# PY32F040xx register map
Vendor: Puya; Series: PY32F0; File version: 1.0.0
CPU: CM0+ r0p1, little endian, no MPU, no FPU, 4 interrupt priority bits
Registers are 32-bit, read-write, reset 0x0 unless marked. A register's access mark holds for its fields unless they carry their own. Offsets are from the block's base; [hi:lo] are bit positions; {n}, {i} and the like mark numbered series; 'fields as' and 'values as' point back to an identical list.

## COMP1 — Comparator 1
Base 0x40010200
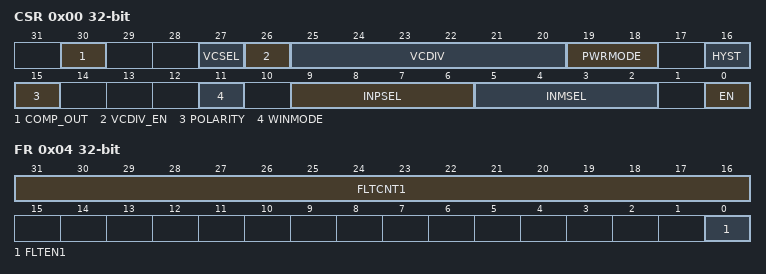
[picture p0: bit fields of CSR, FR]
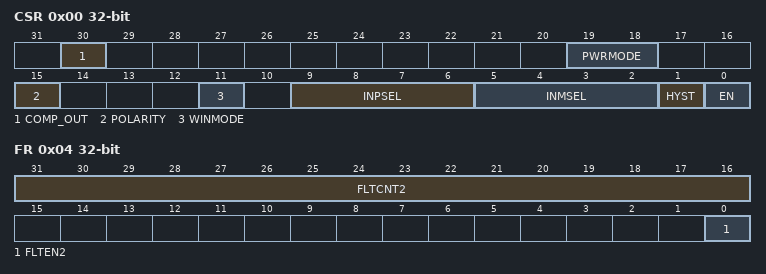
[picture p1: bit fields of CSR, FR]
0x00 CSR — COMP control and status register
  [30] COMP_OUT — Comparator output status
  [27] VCSEL
  [26] VCDIV_EN
  [25:20] VCDIV
    1=0; 2=1; 4=2; 8=3; 16=4; 32=5
  [19:18] PWRMODE — Comparator power mode selector
    1=0; 2=1
  [16] HYST — Comparator hysteresis enable selector
  [15] POLARITY — Comparator polarity selector
  [11] WINMODE — Comparator non-inverting input selector for window mode
  [9:6] INPSEL — Comparator signal selector for non-inverting input
    1=0; 2=1; 4=2; 8=3
  [5:2] INMSEL — Comparator signal selector for inverting input INM
  [0] EN — COMP enable bit
0x04 FR — Comparator Filter register
  [31:16] FLTCNT1 — Comparator filter and counter
  [0] FLTEN1 — Filter enable bit

## COMP2 — Comparator2
Base 0x40010210
0x00 CSR — COMP control and status register
  [30] COMP_OUT — Comparator output status
  [19:18] PWRMODE — Comparator power mode selector
    1=0; 2=1
  [15] POLARITY — Comparator polarity selector
  [11] WINMODE — Comparator non-inverting input selector for window mode
  [9:6] INPSEL — Comparator signal selector for non-inverting input
    1=0; 2=1; 4=2; 8=3
  [5:2] INMSEL — Comparator signal selector for inverting input INM
  [1] HYST — Comparator hysteresis enable selector
  [0] EN — COMP enable bit
0x04 FR — Comparator Filter register
  [31:16] FLTCNT2 — Comparator filter and counter
  [0] FLTEN2 — Filter enable bit

## CRC — CRC calculation unit
Base 0x40023000
0x00 DR reset 0xFFFFFFFF — Data register
  [31:0] DR — Data Register
0x04 IDR — Independent Data register
  [7:0] IDR
0x08 CR wo — Control register
  [0] RESET — Reset bit

## CTC
Base 0x40006C00
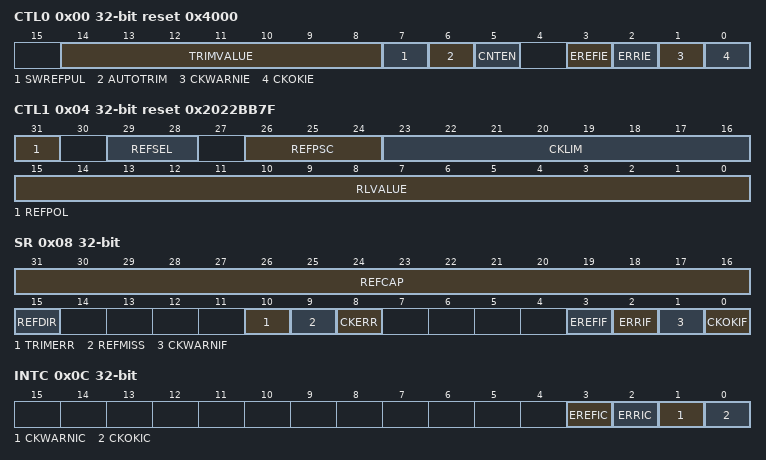
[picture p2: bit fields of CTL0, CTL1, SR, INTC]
0x00 CTL0 reset 0x4000
  [14:8] TRIMVALUE, [7] SWREFPUL wo, [6] AUTOTRIM, [5] CNTEN, [3] EREFIE, [2] ERRIE, [1] CKWARNIE, [0] CKOKIE
0x04 CTL1 reset 0x2022BB7F
  [31] REFPOL
  [29:28] REFSEL
    1=0; 2=1
  [26:24] REFPSC
    1=0; 2=1; 4=2
  [23:16] CKLIM
  [15:0] RLVALUE
0x08 SR ro
  [31:16] REFCAP, [15] REFDIR, [10] TRIMERR, [9] REFMISS, [8] CKERR, [3] EREFIF, [2] ERRIF, [1] CKWARNIF, [0] CKOKIF
0x0C INTC wo
  [3] EREFIC, [2] ERRIC, [1] CKWARNIC, [0] CKOKIC

## DBGMCU — Debug support
Base 0x40015800
0x00 IDCODE ro — MCU Device ID Code Register
  [30:0] REV_ID
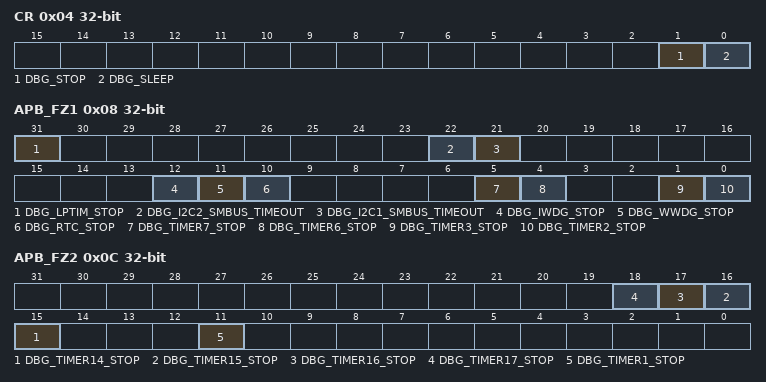
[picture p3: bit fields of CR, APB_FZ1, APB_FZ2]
0x04 CR — Debug MCU Configuration Register
  [1] DBG_STOP — Debug Stop Mode
  [0] DBG_SLEEP — Debug Sleep Mode
0x08 APB_FZ1 — APB Freeze Register1
  [31] DBG_LPTIM_STOP — Debug LPTIM stopped when Core is halted
  [22] DBG_I2C2_SMBUS_TIMEOUT ro
  [21] DBG_I2C1_SMBUS_TIMEOUT
  [12] DBG_IWDG_STOP — Debug Independent Wachdog stopped when Core is halted
  [11] DBG_WWDG_STOP — Debug Window Wachdog stopped when Core is halted
  [10] DBG_RTC_STOP — Debug RTC stopped when Core is halted
  [5] DBG_TIMER7_STOP — Debug Timer 7 stopped when Core is halted
  [4] DBG_TIMER6_STOP — Debug Timer 6 stopped when Core is halted
  [1] DBG_TIMER3_STOP — Debug Timer 3 stopped when Core is halted
  [0] DBG_TIMER2_STOP — Debug Timer 2 stopped when Core is halted
0x0C APB_FZ2 — APB Freeze Register2
  [n+1] DBG_TIMER{n}_STOP (n=14..17) — Debug Timer {n} stopped when Core is halted
  [11] DBG_TIMER1_STOP — Debug Timer 1 stopped when Core is halted

## DIV — Hardware Divider
Base 0x40023800
0x00 DEND — Dividend
0x04 SOR — Divisor
0x08 QUOT ro — Quotient
0x0C REMA ro — Remainder
0x10 SIGN — des SIGN
  [0] DIV_SIGN — des DIV_SIGN
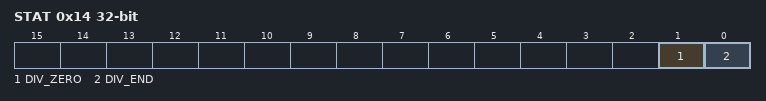
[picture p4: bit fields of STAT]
0x14 STAT — des SIGN
  [1] DIV_ZERO — des DIV_ZERO
  [0] DIV_END — des DIV_END

## DMA — Direct memory access
Base 0x40020000
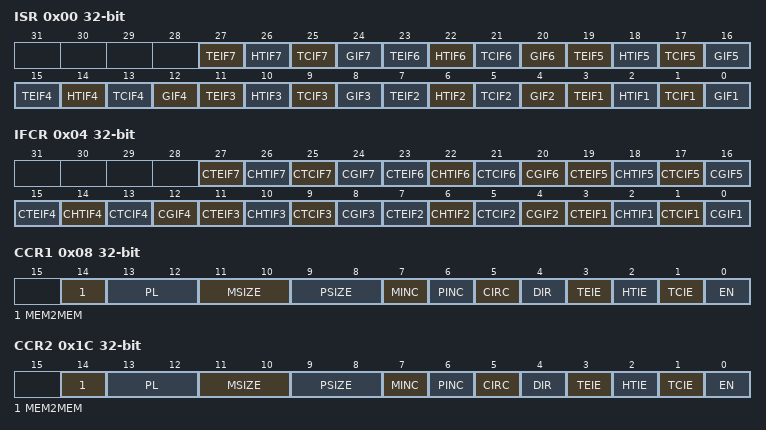
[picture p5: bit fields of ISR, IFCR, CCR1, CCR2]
0x00 ISR ro
  [4n-1] TEIF{n} (n=1..7), [4n-2] HTIF{n} (n=1..7), [4n-3] TCIF{n} (n=1..7), [4n-4] GIF{n} (n=1..7)
0x04 IFCR wo
  [4n-1] CTEIF{n} (n=1..7), [4n-2] CHTIF{n} (n=1..7), [4n-3] CTCIF{n} (n=1..7), [4n-4] CGIF{n} (n=1..7)
0x08 CCR1
  [14] MEM2MEM, [13:12] PL, [11:10] MSIZE, [9:8] PSIZE, [7] MINC, [6] PINC, [5] CIRC, [4] DIR, [3] TEIE, [2] HTIE, [1] TCIE, [0] EN
0x0C CNDTR1
  [15:0] NDT
0x10 CPAR1
  [31:0] PA
{0x0+0x14*i} CMAR{i} (i=1..7)
  [31:0] MA
0x1C CCR2
  fields as CCR1
0x20 CNDTR2
  [15:0] NDT
0x24 CPAR2
  [31:0] PA
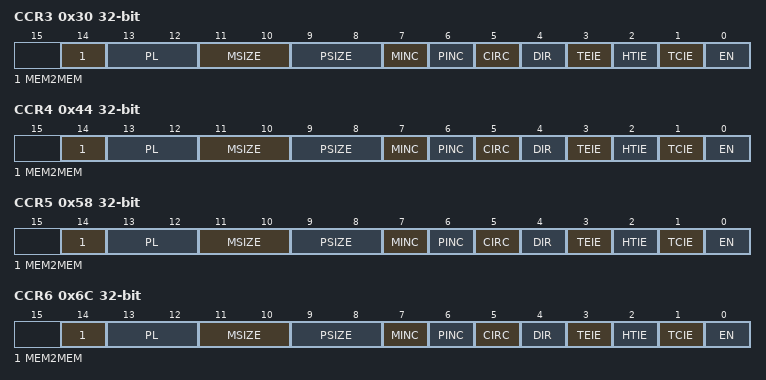
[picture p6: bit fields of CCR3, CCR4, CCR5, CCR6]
0x30 CCR3
  fields as CCR1
0x34 CNDTR3
  [15:0] NDT
0x38 CPAR3
  [31:0] PA
0x44 CCR4
  fields as CCR1
0x48 CNDTR4
  [15:0] NDT
0x4C CPAR4
  [31:0] PA
0x58 CCR5
  fields as CCR1
0x5C CNDTR5
  [15:0] NDT
0x60 CPAR5
  [31:0] PA
0x6C CCR6
  fields as CCR1
0x70 CNDTR6
  [15:0] NDT
0x74 CPAR6
  [31:0] PA
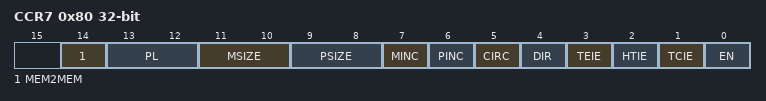
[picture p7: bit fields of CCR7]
0x80 CCR7
  fields as CCR1
0x84 CNDTR7
  [15:0] NDT
0x88 CPAR7
  [31:0] PA
